AUTOSAR XML (schema 4-0-3)
standard types defined: UInt32, UInt8
package /AUTOSAR_Platform/DataConstrs
  range DC_UInt8: raw 0..255
package /PATAC/Facility/DataTypes/Implementation
  unit NoUnit: factor-si-to-unit=1, offset-si-to-unit=0
package /PATAC/MSM/ComponentTypes
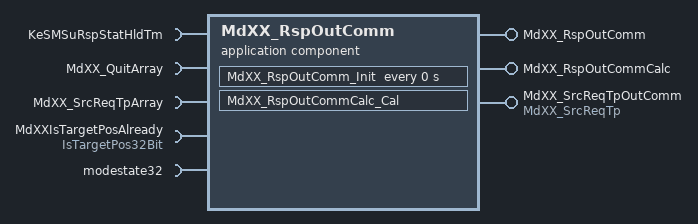
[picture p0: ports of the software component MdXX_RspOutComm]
  application sw component type MdXX_RspOutComm
    provide port MdXX_RspOutComm: provided-interface=MdXX_RspOutComm
      provided-com-specs:
        data-element=Md1_RspOutComm, init-value=0
        data-element=Md{10..19}_RspOutComm, init-value=0
        data-element=Md2_RspOutComm, init-value=0
        data-element=Md{20..29}_RspOutComm, init-value=0
        data-element=Md3_RspOutComm, init-value=0
        data-element=Md{30..32}_RspOutComm, init-value=0
        data-element=Md{4..9}_RspOutComm, init-value=0
    provide port MdXX_RspOutCommCalc: server-com-spec{operation=Cal, queue-length=1}, provided-interface=MdXX_RspOutCommCalc
    provide port MdXX_SrcReqTpOutComm: provided-interface=MdXX_SrcReqTp
      provided-com-specs:
        data-element=Md1_SrcTp, init-value=0
        data-element=Md{10..19}_SrcTp, init-value=0
        data-element=Md2_SrcTp, init-value=0
        data-element=Md{20..29}_SrcTp, init-value=0
        data-element=Md3_SrcTp, init-value=0
        data-element=Md{30..32}_SrcTp, init-value=0
        data-element=Md{4..9}_SrcTp, init-value=0
    5 x require port:
      KeSMSuRspStatHldTm: parameter-require-com-spec{init-value=100, parameter=Val}, required-interface=KeSMSuRspStatHldTm
      MdXX_QuitArray: nonqueued-receiver-com-spec{data-element=MdXX_QuitArray/Val, filter=data-filter-type=ALWAYS, init-value=32 x 0}, required-interface=MdXX_QuitArray
      MdXX_SrcReqTpArray: nonqueued-receiver-com-spec{data-element=MdXX_SrcReqTpArray/Val, filter=data-filter-type=ALWAYS, init-value=32 x 0}, required-interface=MdXX_SrcReqTpArray
      MdXXIsTargetPosAlready: nonqueued-receiver-com-spec{data-element=IsTargetPos32Bit/Val, filter=data-filter-type=ALWAYS, init-value=0}, required-interface=IsTargetPos32Bit
      modestate32: nonqueued-receiver-com-spec{data-element=modestate32/Val, filter=data-filter-type=ALWAYS, init-value=0}, required-interface=modestate32
    behavior MdXX_RspOutComm_InternalBehavior
      timing event MdXX_RspOutComm_InitEvent: start-on-event=MdXX_RspOutComm_Init, period=0
      operation invoked event OIT_MdXX_RspOutCommCalc_Cal_MdXX_RspOutCommCalc_Cal: start-on-event=MdXX_RspOutCommCalc_Cal, operation=MdXX_RspOutCommCalc.Cal
      runnable MdXX_RspOutComm_Init
        parameter access PA_KeSMSuRspStatHldTm_Val: accessed-parameter=KeSMSuRspStatHldTm.Val
      runnable MdXX_RspOutCommCalc_Cal
        data-receive-point-by-arguments:
          4 x access:
            REC_MdXX_QuitArray_Val: accessed-variable=MdXX_QuitArray.Val
            REC_MdXX_SrcReqTpArray_Val: accessed-variable=MdXX_SrcReqTpArray.Val
            REC_MdXXIsTargetPosAlready_Val: accessed-variable=MdXXIsTargetPosAlready.Val
            REC_modestate32_Val: accessed-variable=modestate32.Val
        data-send-points:
          64 x access:
            SEND_MdXX_RspOutComm_Md1_RspOutComm: accessed-variable=MdXX_RspOutComm.Md1_RspOutComm
            SEND_MdXX_RspOutComm_Md{10..19}_RspOutComm: accessed-variable=MdXX_RspOutComm.Md{10..19}_RspOutComm
            SEND_MdXX_RspOutComm_Md2_RspOutComm: accessed-variable=MdXX_RspOutComm.Md2_RspOutComm
            SEND_MdXX_RspOutComm_Md{20..29}_RspOutComm: accessed-variable=MdXX_RspOutComm.Md{20..29}_RspOutComm
            SEND_MdXX_RspOutComm_Md3_RspOutComm: accessed-variable=MdXX_RspOutComm.Md3_RspOutComm
            SEND_MdXX_RspOutComm_Md{30..32}_RspOutComm: accessed-variable=MdXX_RspOutComm.Md{30..32}_RspOutComm
            SEND_MdXX_RspOutComm_Md{4..9}_RspOutComm: accessed-variable=MdXX_RspOutComm.Md{4..9}_RspOutComm
            SEND_MdXX_SrcReqTpOutComm_Md1_SrcTp: accessed-variable=MdXX_SrcReqTpOutComm.Md1_SrcTp
            SEND_MdXX_SrcReqTpOutComm_Md{10..19}_SrcTp: accessed-variable=MdXX_SrcReqTpOutComm.Md{10..19}_SrcTp
            SEND_MdXX_SrcReqTpOutComm_Md2_SrcTp: accessed-variable=MdXX_SrcReqTpOutComm.Md2_SrcTp
            SEND_MdXX_SrcReqTpOutComm_Md{20..29}_SrcTp: accessed-variable=MdXX_SrcReqTpOutComm.Md{20..29}_SrcTp
            SEND_MdXX_SrcReqTpOutComm_Md3_SrcTp: accessed-variable=MdXX_SrcReqTpOutComm.Md3_SrcTp
            SEND_MdXX_SrcReqTpOutComm_Md{30..32}_SrcTp: accessed-variable=MdXX_SrcReqTpOutComm.Md{30..32}_SrcTp
            SEND_MdXX_SrcReqTpOutComm_Md{4..9}_SrcTp: accessed-variable=MdXX_SrcReqTpOutComm.Md{4..9}_SrcTp
        parameter access PA_KeSMSuRspStatHldTm_Val: accessed-parameter=KeSMSuRspStatHldTm.Val
  swc implementation MdXX_RspOutComm_Implementation: behavior=MdXX_RspOutComm_InternalBehavior
    code-descriptors:
      code Default: artifact-descriptors=autosar-engineering-object={short-label=Default, category=SWSRC}
package /PATAC/MSM/ModeAdjust/CalPortInterface
  parameter interface KeSMSuRspStatHldTm
    parameter data prototype Val: sw-calibration-access=READ-WRITE, type=UInt8
package /PATAC/MSM/ModeAdjust/CompuMethods
  compu method MdRspLocal2: 0=MdRsp_None, 1=MdRsp_RecallSuccessfully, 2=MdRsp_RecallUnsuccessfully_LocalInterrupt, 3=MdRsp_RecallUnsuccessfully_NonEnghSpace, 4=MdRsp_RecallOngoing, 5=MdRsp_TargetPositionAlready, 6=MdRsp_LowPower, 7=MdRsp_CrashStat, 8=MdRsp_ThdRwOccupt, 9=MdRsp_PosNotLrn, 10=MdRsp_NotParkStat, 11=MdRsp_SpdNotCorrt
package /PATAC/MSM/ModeAdjust/DataType
  4 x impl type, all with sw-calibration-access=READ-ONLY, type-emitter=RTE:
    Array1x32_MdRspLocal2: category=ARRAY
      element Element: array-size=32, array-size-semantics=FIXED-SIZE, compu-method=MdRspLocal2, implementation-data-type=MdRspLocal2
    array1x32_SrcReqTp: category=ARRAY
      element Element: array-size=32, array-size-semantics=FIXED-SIZE, implementation-data-type=SrcReqTp1
    MdRspLocal2: category=VALUE, base-type=UInt8, compu-method=MdRspLocal2
    SrcReqTp1: category=VALUE, base-type=UInt8, compu {0=SrcReqTp_None, 1=SrcReqTp_Local, 2=SrcReqTp_HMI2L, 3=SrcReqTp_HMI2R, 4=SrcReqTp_HMI, 5=SrcReqTp_Remote, 6=SrcReqTp_SRS}
package /PATAC/MSM/ModeAdjust/PortInterface
  client server interface MdXX_RspOutCommCalc
    operation Cal
  6 x sender receiver interface:
    IsTargetPos32Bit: invalidation-policy{data-element=IsTargetPos32Bit/Val, handle-invalid=DONT-INVALIDATE}
      data Val: type=UInt32
    MdXX_QuitArray: invalidation-policy{data-element=MdXX_QuitArray/Val, handle-invalid=DONT-INVALIDATE}
      data Val: type=Array1x32_MdRspLocal2
    MdXX_RspOutComm
      32 x data, all with type=UInt8:
        Md1_RspOutComm
        Md{10..19}_RspOutComm
        Md2_RspOutComm
        Md{20..29}_RspOutComm
        Md3_RspOutComm
        Md{30..32}_RspOutComm
        Md{4..9}_RspOutComm
      invalidation-policys:
        data-element=Md1_RspOutComm, handle-invalid=DONT-INVALIDATE
        data-element=Md{10..19}_RspOutComm, handle-invalid=DONT-INVALIDATE
        data-element=Md2_RspOutComm, handle-invalid=DONT-INVALIDATE
        data-element=Md{20..29}_RspOutComm, handle-invalid=DONT-INVALIDATE
        data-element=Md3_RspOutComm, handle-invalid=DONT-INVALIDATE
        data-element=Md{30..32}_RspOutComm, handle-invalid=DONT-INVALIDATE
        data-element=Md{4..9}_RspOutComm, handle-invalid=DONT-INVALIDATE
    MdXX_SrcReqTp
      32 x data, all with type=SrcReqTp1:
        Md1_SrcTp
        Md{10..19}_SrcTp
        Md2_SrcTp
        Md{20..29}_SrcTp
        Md3_SrcTp
        Md{30..32}_SrcTp
        Md{4..9}_SrcTp
      invalidation-policys:
        data-element=Md1_SrcTp, handle-invalid=DONT-INVALIDATE
        data-element=Md{10..19}_SrcTp, handle-invalid=DONT-INVALIDATE
        data-element=Md2_SrcTp, handle-invalid=DONT-INVALIDATE
        data-element=Md{20..29}_SrcTp, handle-invalid=DONT-INVALIDATE
        data-element=Md3_SrcTp, handle-invalid=DONT-INVALIDATE
        data-element=Md{30..32}_SrcTp, handle-invalid=DONT-INVALIDATE
        data-element=Md{4..9}_SrcTp, handle-invalid=DONT-INVALIDATE
    MdXX_SrcReqTpArray: invalidation-policy{data-element=MdXX_SrcReqTpArray/Val, handle-invalid=DONT-INVALIDATE}
      data Val: type=array1x32_SrcReqTp
    modestate32: invalidation-policy{data-element=modestate32/Val, handle-invalid=DONT-INVALIDATE}
      data Val: type=UInt32
